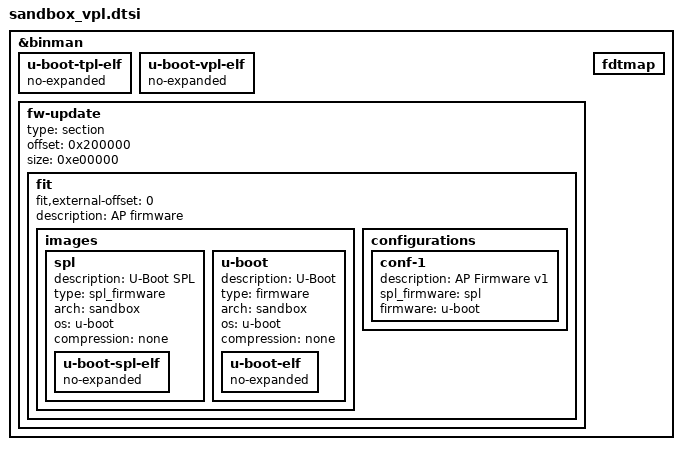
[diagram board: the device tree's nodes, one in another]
// SPDX-License-Identifier: GPL-2.0+
/*
 * Devicetree file for VPL (Verifying Program Loader)
 */

&binman {
	u-boot-tpl-elf {
		no-expanded;
	};
	u-boot-vpl-elf {
		no-expanded;
	};
	fw-update {
		type = "section";
		offset = <0x200000>;
		size = <0xe00000>;

		fit {
			fit,external-offset = <0>;
			description = "AP firmware";
			images {
				spl {
					description = "U-Boot SPL";
					type = "spl_firmware";
					arch = "sandbox";
					os = "u-boot";
					compression = "none";

					u-boot-spl-elf {
						no-expanded;
					};
				};
				u-boot {
					description = "U-Boot";
					type = "firmware";
					arch = "sandbox";
					os = "u-boot";
					compression = "none";

					u-boot-elf {
						no-expanded;
					};
				};
			};

			configurations {
				conf-1 {
					description = "AP Firmware v1";
					spl_firmware = "spl";
					firmware = "u-boot";
				};
			};
		};
	};
	fdtmap {
	};
};
